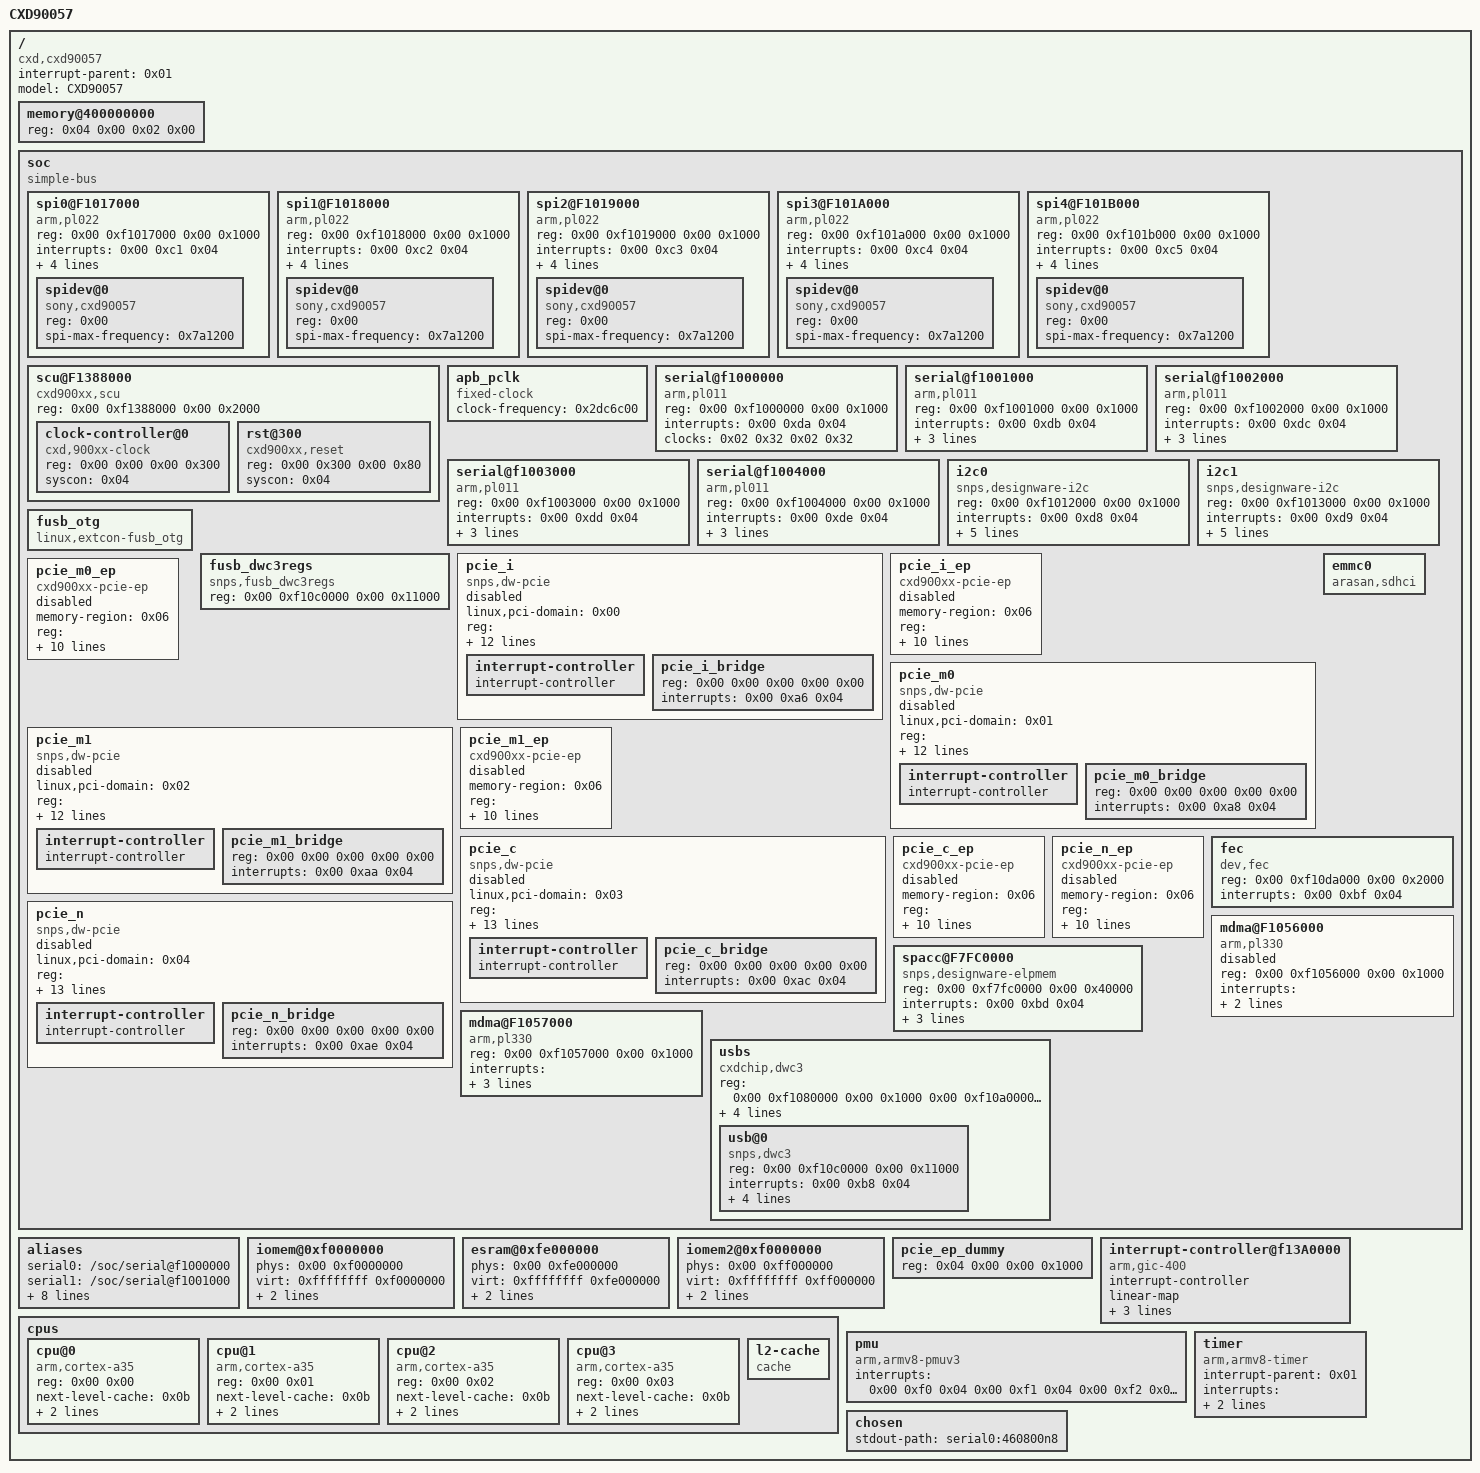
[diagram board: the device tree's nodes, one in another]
/dts-v1/;

/ {
	compatible = "cxd,cxd90057";
	interrupt-parent = <0x01>;
	#address-cells = <0x02>;
	#size-cells = <0x02>;
	model = "CXD90057";

	memory@400000000 {
		device_type = "memory";
		reg = <0x04 0x00 0x02 0x00>;
	};

	soc {
		compatible = "simple-bus";
		#address-cells = <0x02>;
		#size-cells = <0x02>;
		ranges;

		spi0@F1017000 {
			compatible = "arm,pl022", "arm,primecell";
			reg = <0x00 0xf1017000 0x00 0x1000>;
			interrupts = <0x00 0xc1 0x04>;
			#address-cells = <0x01>;
			#size-cells = <0x00>;
			num-cs = <0x01>;
			clocks = <0x02 0x0a 0x02 0x61 0x02 0x37 0x02 0x37>;
			clock-names = "spi_clk_parent", "spi_clk_sel", "spi_clk", "apb_pclk";
			resets = <0x03 0xac 0x03 0xad>;
			reset-names = "ssp", "apb";
			status = "okay";

			spidev@0 {
				compatible = "sony,cxd90057";
				reg = <0x00>;
				spi-max-frequency = <0x7a1200>;
			};
		};

		spi1@F1018000 {
			compatible = "arm,pl022", "arm,primecell";
			reg = <0x00 0xf1018000 0x00 0x1000>;
			interrupts = <0x00 0xc2 0x04>;
			#address-cells = <0x01>;
			#size-cells = <0x00>;
			num-cs = <0x01>;
			clocks = <0x02 0x0a 0x02 0x62 0x02 0x38 0x02 0x38>;
			clock-names = "spi_clk_parent", "spi_clk_sel", "spi_clk", "apb_pclk";
			resets = <0x03 0xae 0x03 0xaf>;
			reset-names = "ssp", "apb";
			status = "okay";

			spidev@0 {
				compatible = "sony,cxd90057";
				reg = <0x00>;
				spi-max-frequency = <0x7a1200>;
			};
		};

		spi2@F1019000 {
			compatible = "arm,pl022", "arm,primecell";
			reg = <0x00 0xf1019000 0x00 0x1000>;
			interrupts = <0x00 0xc3 0x04>;
			#address-cells = <0x01>;
			#size-cells = <0x00>;
			num-cs = <0x01>;
			clocks = <0x02 0x0a 0x02 0x63 0x02 0x39 0x02 0x39>;
			clock-names = "spi_clk_parent", "spi_clk_sel", "spi_clk", "apb_pclk";
			resets = <0x03 0xb0 0x03 0xb1>;
			reset-names = "ssp", "apb";
			status = "okay";

			spidev@0 {
				compatible = "sony,cxd90057";
				reg = <0x00>;
				spi-max-frequency = <0x7a1200>;
			};
		};

		spi3@F101A000 {
			compatible = "arm,pl022", "arm,primecell";
			reg = <0x00 0xf101a000 0x00 0x1000>;
			interrupts = <0x00 0xc4 0x04>;
			#address-cells = <0x01>;
			#size-cells = <0x00>;
			num-cs = <0x01>;
			clocks = <0x02 0x0a 0x02 0x64 0x02 0x3a 0x02 0x3a>;
			clock-names = "spi_clk_parent", "spi_clk_sel", "spi_clk", "apb_pclk";
			resets = <0x03 0xb2 0x03 0xb3>;
			reset-names = "ssp", "apb";
			status = "okay";

			spidev@0 {
				compatible = "sony,cxd90057";
				reg = <0x00>;
				spi-max-frequency = <0x7a1200>;
			};
		};

		spi4@F101B000 {
			compatible = "arm,pl022", "arm,primecell";
			reg = <0x00 0xf101b000 0x00 0x1000>;
			interrupts = <0x00 0xc5 0x04>;
			#address-cells = <0x01>;
			#size-cells = <0x00>;
			num-cs = <0x01>;
			clocks = <0x02 0x0a 0x02 0x65 0x02 0x3b 0x02 0x3b>;
			clock-names = "spi_clk_parent", "spi_clk_sel", "spi_clk", "apb_pclk";
			resets = <0x03 0xb4 0x03 0xb5>;
			reset-names = "ssp", "apb";
			status = "okay";

			spidev@0 {
				compatible = "sony,cxd90057";
				reg = <0x00>;
				spi-max-frequency = <0x7a1200>;
			};
		};

		scu@F1388000 {
			#address-cells = <0x02>;
			#size-cells = <0x02>;
			compatible = "cxd900xx,scu", "syscon", "simple-mfd";
			reg = <0x00 0xf1388000 0x00 0x2000>;
			ranges;
			linux,phandle = <0x04>;
			phandle = <0x04>;

			clock-controller@0 {
				compatible = "cxd,900xx-clock";
				reg = <0x00 0x00 0x00 0x300>;
				#clock-cells = <0x01>;
				syscon = <0x04>;
				linux,phandle = <0x02>;
				phandle = <0x02>;
			};

			rst@300 {
				compatible = "cxd900xx,reset";
				reg = <0x00 0x300 0x00 0x80>;
				#reset-cells = <0x01>;
				syscon = <0x04>;
				linux,phandle = <0x03>;
				phandle = <0x03>;
			};
		};

		apb_pclk {
			compatible = "fixed-clock";
			#clock-cells = <0x00>;
			clock-frequency = <0x2dc6c00>;
			linux,phandle = <0x09>;
			phandle = <0x09>;
		};

		serial@f1000000 {
			compatible = "arm,pl011", "arm,primecell";
			reg = <0x00 0xf1000000 0x00 0x1000>;
			interrupts = <0x00 0xda 0x04>;
			clocks = <0x02 0x32 0x02 0x32>;
			clock-names = "uartclk", "apb_pclk";
		};

		serial@f1001000 {
			compatible = "arm,pl011", "arm,primecell";
			reg = <0x00 0xf1001000 0x00 0x1000>;
			interrupts = <0x00 0xdb 0x04>;
			clocks = <0x02 0x33 0x02 0x33>;
			clock-names = "uartclk", "apb_pclk";
			assigned-clocks = <0x02 0x58>;
			assigned-clock-parents = <0x02 0x0a>;
		};

		serial@f1002000 {
			compatible = "arm,pl011", "arm,primecell";
			reg = <0x00 0xf1002000 0x00 0x1000>;
			interrupts = <0x00 0xdc 0x04>;
			clocks = <0x02 0x34 0x02 0x34>;
			clock-names = "uartclk", "apb_pclk";
			assigned-clocks = <0x02 0x59>;
			assigned-clock-parents = <0x02 0x0a>;
		};

		serial@f1003000 {
			compatible = "arm,pl011", "arm,primecell";
			reg = <0x00 0xf1003000 0x00 0x1000>;
			interrupts = <0x00 0xdd 0x04>;
			clocks = <0x02 0x35 0x02 0x35>;
			clock-names = "uartclk", "apb_pclk";
			assigned-clocks = <0x02 0x5a>;
			assigned-clock-parents = <0x02 0x0a>;
		};

		serial@f1004000 {
			compatible = "arm,pl011", "arm,primecell";
			reg = <0x00 0xf1004000 0x00 0x1000>;
			interrupts = <0x00 0xde 0x04>;
			clocks = <0x02 0x36 0x02 0x36>;
			clock-names = "uartclk", "apb_pclk";
			assigned-clocks = <0x02 0x5b>;
			assigned-clock-parents = <0x02 0x0a>;
		};

		i2c0 {
			#address-cells = <0x01>;
			#size-cells = <0x00>;
			compatible = "snps,designware-i2c";
			reg = <0x00 0xf1012000 0x00 0x1000>;
			interrupts = <0x00 0xd8 0x04>;
			clocks = <0x02 0x3c>;
			clock-names = "i2c_clk";
			clock-frequency = <0x61a80>;
			resets = <0x03 0xb8>;
			reset-names = "i2c_rst";
			i2c-scl-stuck-at-low-timeout = <0x16e3600>;
			i2c-sda-stuck-at-low-timeout = "", "\aS";
			status = "okay";
		};

		i2c1 {
			#address-cells = <0x01>;
			#size-cells = <0x00>;
			compatible = "snps,designware-i2c";
			reg = <0x00 0xf1013000 0x00 0x1000>;
			interrupts = <0x00 0xd9 0x04>;
			clocks = <0x02 0x3d>;
			clock-names = "i2c_clk";
			clock-frequency = <0x61a80>;
			resets = <0x03 0xb9>;
			reset-names = "i2c_rst";
			i2c-scl-stuck-at-low-timeout = "", "\aS";
			i2c-sda-stuck-at-low-timeout = "", "\aS";
			status = "okay";
		};

		fusb_otg {
			compatible = "linux,extcon-fusb_otg";
			linux,phandle = <0x0a>;
			phandle = <0x0a>;
		};

		fusb_dwc3regs {
			compatible = "snps,fusb_dwc3regs";
			reg = <0x00 0xf10c0000 0x00 0x11000>;
		};

		pcie_i {
			compatible = "snps,dw-pcie";
			linux,pci-domain = <0x00>;
			reg = <0x00 0xf7000000 0x00 0x380000 0x00 0xdffc0000 0x00 0x20000 0x00 0xf11c0000 0x00 0x40000>;
			reg-names = "ctrlreg", "config", "phy_reg";
			#address-cells = <0x03>;
			#size-cells = <0x02>;
			device_type = "pci";
			ranges = <0x82000000 0x00 0xdffe0000 0x00 0xdffe0000 0x00 0x10000>;
			interrupts = <0x00 0xa6 0x04 0x00 0xa6 0x04>;
			#interrupt-cells = <0x01>;
			interrupt-map-mask = <0x00 0x00 0x00 0x07>;
			interrupt-map = <0x00 0x00 0x00 0x00 0x01 0x00 0xa6 0x04 0x00 0x00 0x00 0x01 0x05 0x00 0x00 0x00 0x00 0x02 0x05 0x01 0x00 0x00 0x00 0x03 0x05 0x02 0x00 0x00 0x00 0x04 0x05 0x03>;
			firm-id = <0x01>;
			num-lanes = <0x04>;
			num-viewport = <0x08>;
			resets = <0x03 0x20 0x03 0x21 0x03 0x22 0x03 0x23 0x03 0x76 0x03 0x77>;
			reset-names = "rst_pwrup", "rst_button", "rst_pe", "rst_apb", "rst_axi2avb_pci", "rst_axi2avb_pci_i0";
			clocks = <0x02 0x3e 0x02 0x3f 0x02 0x40 0x02 0x41 0x02 0x42 0x02 0x1d 0x02 0x1e>;
			clock-names = "apb_pclk", "dbi_aclk", "slv_aclk", "mstr_aclk", "aux_clk", "axi2avb_pcie0", "axi2avb_pcie1";
			status = "disabled";

			interrupt-controller {
				interrupt-controller;
				#address-cells = <0x00>;
				#interrupt-cells = <0x01>;
				linux,phandle = <0x05>;
				phandle = <0x05>;
			};

			pcie_i_bridge {
				reg = <0x00 0x00 0x00 0x00 0x00>;
				interrupts = <0x00 0xa6 0x04>;
			};
		};

		pcie_i_ep {
			compatible = "cxd900xx-pcie-ep";
			memory-region = <0x06>;
			reg = <0x00 0xf7000000 0x00 0x400000 0x00 0xf7100000 0x00 0x10000 0x00 0xf11c0000 0x00 0x40000>;
			reg-names = "ctrlreg", "ctrlreg_shadow", "phy_reg";
			interrupts = <0x00 0xa6 0x04>;
			firm-id = <0x01>;
			num-lanes = <0x04>;
			num-ib-windows = <0x08>;
			num-ob-windows = <0x08>;
			resets = <0x03 0x20 0x03 0x21 0x03 0x22 0x03 0x23 0x03 0x76 0x03 0x77>;
			reset-names = "rst_pwrup", "rst_button", "rst_pe", "rst_apb", "rst_axi2avb_pci", "rst_axi2avb_pci_i0";
			clocks = <0x02 0x3e 0x02 0x3f 0x02 0x40 0x02 0x41 0x02 0x42 0x02 0x1d 0x02 0x1e>;
			clock-names = "apb_pclk", "dbi_aclk", "slv_aclk", "mstr_aclk", "aux_clk", "axi2avb_pcie0", "axi2avb_pcie1";
			status = "disabled";
		};

		pcie_m0 {
			compatible = "snps,dw-pcie";
			linux,pci-domain = <0x01>;
			reg = <0x00 0xf6800000 0x00 0x380000 0x00 0xc8010000 0x00 0x20000 0x00 0xf1140000 0x00 0x40000>;
			reg-names = "ctrlreg", "config", "phy_reg";
			#address-cells = <0x03>;
			#size-cells = <0x02>;
			device_type = "pci";
			ranges = <0x82000000 0x00 0xc8030000 0x00 0xc8030000 0x00 0x3fe0000 0xc2000000 0x00 0xcc010000 0x00 0xcc010000 0x00 0x3fe0000>;
			interrupts = <0x00 0xa8 0x04 0x00 0xa8 0x04>;
			#interrupt-cells = <0x01>;
			interrupt-map-mask = <0x00 0x00 0x00 0x07>;
			interrupt-map = <0x00 0x00 0x00 0x00 0x01 0x00 0xa8 0x04>;
			firm-id = <0x01>;
			num-lanes = <0x02>;
			num-viewport = <0x08>;
			resets = <0x03 0x28 0x03 0x29 0x03 0x2a 0x03 0x2b 0x03 0x76 0x03 0x77>;
			reset-names = "rst_pwrup", "rst_button", "rst_pe", "rst_apb", "rst_axi2avb_pci", "rst_axi2avb_pci_i0";
			clocks = <0x02 0x43 0x02 0x44 0x02 0x45 0x02 0x46 0x02 0x47 0x02 0x1d 0x02 0x1e>;
			clock-names = "apb_pclk", "dbi_aclk", "slv_aclk", "mstr_aclk", "aux_clk", "axi2avb_pcie0", "axi2avb_pcie1";
			status = "disabled";

			interrupt-controller {
				interrupt-controller;
				#address-cells = <0x00>;
				#interrupt-cells = <0x01>;
			};

			pcie_m0_bridge {
				reg = <0x00 0x00 0x00 0x00 0x00>;
				interrupts = <0x00 0xa8 0x04>;
			};
		};

		pcie_m0_ep {
			compatible = "cxd900xx-pcie-ep";
			memory-region = <0x06>;
			reg = <0x00 0xf6800000 0x00 0x400000 0x00 0xf6900000 0x00 0x10000 0x00 0xf1140000 0x00 0x40000>;
			reg-names = "ctrlreg", "ctrlreg_shadow", "phy_reg";
			interrupts = <0x00 0xa8 0x04>;
			firm-id = <0x01>;
			num-lanes = <0x02>;
			num-ib-windows = <0x08>;
			num-ob-windows = <0x08>;
			resets = <0x03 0x28 0x03 0x29 0x03 0x2a 0x03 0x2b 0x03 0x76 0x03 0x77>;
			reset-names = "rst_pwrup", "rst_button", "rst_pe", "rst_apb", "rst_axi2avb_pci", "rst_axi2avb_pci_i0";
			clocks = <0x02 0x43 0x02 0x44 0x02 0x45 0x02 0x46 0x02 0x47 0x02 0x1d 0x02 0x1e>;
			clock-names = "apb_pclk", "dbi_aclk", "slv_aclk", "mstr_aclk", "aux_clk", "axi2avb_pcie0", "axi2avb_pcie1";
			status = "disabled";
		};

		pcie_m1 {
			compatible = "snps,dw-pcie";
			linux,pci-domain = <0x02>;
			reg = <0x00 0xf6c00000 0x00 0x380000 0x00 0xd0010000 0x00 0x20000 0x00 0xf1180000 0x00 0x40000>;
			reg-names = "ctrlreg", "config", "phy_reg";
			#address-cells = <0x03>;
			#size-cells = <0x02>;
			device_type = "pci";
			ranges = <0x82000000 0x00 0xd0030000 0x00 0xd0030000 0x00 0x3fe0000 0xc2000000 0x00 0xd4010000 0x00 0xd4010000 0x00 0x3fe0000>;
			interrupts = <0x00 0xaa 0x04 0x00 0xaa 0x04>;
			#interrupt-cells = <0x01>;
			interrupt-map-mask = <0x00 0x00 0x00 0x07>;
			interrupt-map = <0x00 0x00 0x00 0x00 0x01 0x00 0xaa 0x04>;
			firm-id = <0x01>;
			num-lanes = <0x02>;
			num-viewport = <0x08>;
			resets = <0x03 0x24 0x03 0x25 0x03 0x26 0x03 0x27 0x03 0x76 0x03 0x77>;
			reset-names = "rst_pwrup", "rst_button", "rst_pe", "rst_apb", "rst_axi2avb_pci", "rst_axi2avb_pci_i0";
			clocks = <0x02 0x48 0x02 0x49 0x02 0x4a 0x02 0x4b 0x02 0x4c 0x02 0x1d 0x02 0x1e>;
			clock-names = "apb_pclk", "dbi_aclk", "slv_aclk", "mstr_aclk", "aux_clk", "axi2avb_pcie0", "axi2avb_pcie1";
			status = "disabled";

			interrupt-controller {
				interrupt-controller;
				#address-cells = <0x00>;
				#interrupt-cells = <0x01>;
			};

			pcie_m1_bridge {
				reg = <0x00 0x00 0x00 0x00 0x00>;
				interrupts = <0x00 0xaa 0x04>;
			};
		};

		pcie_m1_ep {
			compatible = "cxd900xx-pcie-ep";
			memory-region = <0x06>;
			reg = <0x00 0xf6c00000 0x00 0x400000 0x00 0xf6d00000 0x00 0x10000 0x00 0xf1180000 0x00 0x40000>;
			reg-names = "ctrlreg", "ctrlreg_shadow", "phy_reg";
			interrupts = <0x00 0xaa 0x04>;
			firm-id = <0x01>;
			num-lanes = <0x02>;
			num-ib-windows = <0x08>;
			num-ob-windows = <0x08>;
			resets = <0x03 0x24 0x03 0x25 0x03 0x26 0x03 0x27 0x03 0x76 0x03 0x77>;
			reset-names = "rst_pwrup", "rst_button", "rst_pe", "rst_apb", "rst_axi2avb_pci", "rst_axi2avb_pci_i0";
			clocks = <0x02 0x48 0x02 0x49 0x02 0x4a 0x02 0x4b 0x02 0x4c 0x02 0x1d 0x02 0x1e>;
			clock-names = "apb_pclk", "dbi_aclk", "slv_aclk", "mstr_aclk", "aux_clk", "axi2avb_pcie0", "axi2avb_pcie1";
			status = "disabled";
		};

		pcie_c {
			compatible = "snps,dw-pcie";
			linux,pci-domain = <0x03>;
			reg = <0x00 0xf7400000 0x00 0x380000 0x00 0xe0000000 0x00 0x20000 0x00 0xf1200000 0x00 0x40000>;
			reg-names = "ctrlreg", "config", "phy_reg";
			#address-cells = <0x03>;
			#size-cells = <0x02>;
			device_type = "pci";
			cxd90057,pci32;
			ranges = <0x82000000 0x00 0xe0020000 0x00 0xe0020000 0x00 0x3ff0000 0xc2000000 0x00 0xe4010000 0x00 0xe4010000 0x00 0x3ff0000>;
			interrupts = <0x00 0xac 0x04 0x00 0xac 0x04>;
			#interrupt-cells = <0x01>;
			interrupt-map-mask = <0x00 0x00 0x00 0x07>;
			interrupt-map = <0x00 0x00 0x00 0x00 0x01 0x00 0xac 0x04 0x00 0x00 0x00 0x01 0x07 0x00 0x00 0x00 0x00 0x02 0x07 0x01 0x00 0x00 0x00 0x03 0x07 0x02 0x00 0x00 0x00 0x04 0x07 0x03>;
			firm-id = <0x01>;
			num-lanes = <0x01>;
			num-viewport = <0x08>;
			resets = <0x03 0x2c 0x03 0x2d 0x03 0x2e 0x03 0x2f 0x03 0x76 0x03 0x77>;
			reset-names = "rst_pwrup", "rst_button", "rst_pe", "rst_apb", "rst_axi2avb_pci", "rst_axi2avb_pci_i0";
			clocks = <0x02 0x4d 0x02 0x4e 0x02 0x4f 0x02 0x50 0x02 0x51 0x02 0x1d 0x02 0x1e>;
			clock-names = "apb_pclk", "dbi_aclk", "slv_aclk", "mstr_aclk", "aux_clk", "axi2avb_pcie0", "axi2avb_pcie1";
			status = "disabled";

			interrupt-controller {
				interrupt-controller;
				#address-cells = <0x00>;
				#interrupt-cells = <0x01>;
				linux,phandle = <0x07>;
				phandle = <0x07>;
			};

			pcie_c_bridge {
				reg = <0x00 0x00 0x00 0x00 0x00>;
				interrupts = <0x00 0xac 0x04>;
			};
		};

		pcie_c_ep {
			compatible = "cxd900xx-pcie-ep";
			memory-region = <0x06>;
			reg = <0x00 0xf7400000 0x00 0x400000 0x00 0xf7500000 0x00 0x10000 0x00 0xf1200000 0x00 0x40000>;
			reg-names = "ctrlreg", "ctrlreg_shadow", "phy_reg";
			interrupts = <0x00 0xac 0x04>;
			firm-id = <0x01>;
			num-lanes = <0x01>;
			num-ib-windows = <0x08>;
			num-ob-windows = <0x08>;
			resets = <0x03 0x2c 0x03 0x2d 0x03 0x2e 0x03 0x2f 0x03 0x76 0x03 0x77>;
			reset-names = "rst_pwrup", "rst_button", "rst_pe", "rst_apb", "rst_axi2avb_pci", "rst_axi2avb_pci_i0";
			clocks = <0x02 0x4d 0x02 0x4e 0x02 0x4f 0x02 0x50 0x02 0x51 0x02 0x1d 0x02 0x1e>;
			clock-names = "apb_pclk", "dbi_aclk", "slv_aclk", "mstr_aclk", "aux_clk", "axi2avb_pcie0", "axi2avb_pcie1";
			status = "disabled";
		};

		pcie_n {
			compatible = "snps,dw-pcie";
			linux,pci-domain = <0x04>;
			reg = <0x00 0xf6400000 0x00 0x380000 0x00 0xc0000000 0x00 0x20000 0x00 0xf1100000 0x00 0x40000>;
			reg-names = "ctrlreg", "config", "phy_reg";
			#address-cells = <0x03>;
			#size-cells = <0x02>;
			device_type = "pci";
			cxd90057,pci32;
			ranges = <0x82000000 0x00 0xc2000000 0x00 0xc2000000 0x00 0x3000000 0xc2000000 0x00 0xc5000000 0x00 0xc5000000 0x00 0x3000000>;
			interrupts = <0x00 0xae 0x04 0x00 0xae 0x04>;
			#interrupt-cells = <0x01>;
			interrupt-map-mask = <0x00 0x00 0x00 0x07>;
			interrupt-map = <0x00 0x00 0x00 0x00 0x01 0x00 0xae 0x04 0x00 0x00 0x00 0x01 0x08 0x00 0x00 0x00 0x00 0x02 0x08 0x01 0x00 0x00 0x00 0x03 0x08 0x02 0x00 0x00 0x00 0x04 0x08 0x03>;
			firm-id = <0x01>;
			num-lanes = <0x01>;
			num-viewport = <0x08>;
			resets = <0x03 0x30 0x03 0x31 0x03 0x32 0x03 0x33 0x03 0x76 0x03 0x77>;
			reset-names = "rst_pwrup", "rst_button", "rst_pe", "rst_apb", "rst_axi2avb_pci", "rst_axi2avb_pci_i0";
			clocks = <0x02 0x52 0x02 0x53 0x02 0x54 0x02 0x55 0x02 0x56 0x02 0x1d 0x02 0x1e>;
			clock-names = "apb_pclk", "dbi_aclk", "slv_aclk", "mstr_aclk", "aux_clk", "axi2avb_pcie0", "axi2avb_pcie1";
			status = "disabled";

			interrupt-controller {
				interrupt-controller;
				#address-cells = <0x00>;
				#interrupt-cells = <0x01>;
				linux,phandle = <0x08>;
				phandle = <0x08>;
			};

			pcie_n_bridge {
				reg = <0x00 0x00 0x00 0x00 0x00>;
				interrupts = <0x00 0xae 0x04>;
			};
		};

		pcie_n_ep {
			compatible = "cxd900xx-pcie-ep";
			memory-region = <0x06>;
			reg = <0x00 0xf6400000 0x00 0x400000 0x00 0xf6500000 0x00 0x10000 0x00 0xf1100000 0x00 0x40000>;
			reg-names = "ctrlreg", "ctrlreg_shadow", "phy_reg";
			interrupts = <0x00 0xae 0x04>;
			firm-id = <0x01>;
			num-lanes = <0x01>;
			num-ib-windows = <0x08>;
			num-ob-windows = <0x08>;
			resets = <0x03 0x30 0x03 0x31 0x03 0x32 0x03 0x33 0x03 0x76 0x03 0x77>;
			reset-names = "rst_pwrup", "rst_button", "rst_pe", "rst_apb", "rst_axi2avb_pci", "rst_axi2avb_pci_i0";
			clocks = <0x02 0x52 0x02 0x53 0x02 0x54 0x02 0x55 0x02 0x56 0x02 0x1d 0x02 0x1e>;
			clock-names = "apb_pclk", "dbi_aclk", "slv_aclk", "mstr_aclk", "aux_clk", "axi2avb_pcie0", "axi2avb_pcie1";
			status = "disabled";
		};

		emmc0 {
			compatible = "arasan,sdhci";
		};

		fec {
			compatible = "dev,fec";
			reg = <0x00 0xf10da000 0x00 0x2000>;
			interrupts = <0x00 0xbf 0x04>;
		};

		spacc@F7FC0000 {
			compatible = "snps,designware-elpmem";
			reg = <0x00 0xf7fc0000 0x00 0x40000>;
			interrupts = <0x00 0xbd 0x04>;
			dma-coherent;
			clocks = <0x02 0x19>;
			resets = <0x03 0x15>;
			status = "okay";
		};

		mdma@F1056000 {
			compatible = "arm,pl330", "arm,primecell";
			reg = <0x00 0xf1056000 0x00 0x1000>;
			interrupts = <0x00 0x50 0x04 0x00 0x51 0x04 0x00 0x52 0x04 0x00 0x53 0x04 0x00 0x54 0x04 0x00 0x55 0x04 0x00 0x56 0x04 0x00 0x57 0x04>;
			clocks = <0x09>;
			clock-names = "apb_pclk";
			status = "disabled";
			#dma-cells = <0x01>;
		};

		mdma@F1057000 {
			compatible = "arm,pl330", "arm,primecell";
			reg = <0x00 0xf1057000 0x00 0x1000>;
			interrupts = <0x00 0x71 0x04 0x00 0x72 0x04 0x00 0x73 0x04 0x00 0x74 0x04 0x00 0x75 0x04 0x00 0x76 0x04 0x00 0x77 0x04 0x00 0x78 0x04>;
			clocks = <0x09>;
			clock-names = "apb_pclk";
			status = "ok";
			#dma-cells = <0x01>;
			arm,pl330-broken-no-flushp;
		};

		usbs {
			compatible = "cxdchip,dwc3";
			reg = <0x00 0xf1080000 0x00 0x1000 0x00 0xf10a0000 0x00 0x1c000>;
			reg-names = "ss_usb", "phy_cr";
			clocks = <0x02 0x13 0x02 0x12 0x02 0x11 0x02 0x10>;
			clock-names = "usb_sus_clk", "usb_axi_clk", "usb_apb_clk", "usb_refclk";
			resets = <0x03 0x0b 0x03 0x0a 0x03 0x09 0x03 0x08>;
			reset-names = "rst_u31", "rst_u2", "rst_apb", "rst_axi";
			#address-cells = <0x02>;
			#size-cells = <0x02>;
			ranges;

			usb@0 {
				compatible = "snps,dwc3";
				reg = <0x00 0xf10c0000 0x00 0x11000>;
				interrupts = <0x00 0xb8 0x04>;
				dr_mode = "otg";
				maximum-speed = "super-speed-plus";
				phy_type = "utmi";
				extcon = <0x0a>;
				status = "okay";
			};
		};
	};

	aliases {
		serial0 = "/soc/serial@f1000000";
		serial1 = "/soc/serial@f1001000";
		serial2 = "/soc/serial@f1002000";
		serial3 = "/soc/serial@f1003000";
		serial4 = "/soc/serial@f1004000";
		spi0 = "/soc/spi0@F1017000";
		spi1 = "/soc/spi1@F1018000";
		spi2 = "/soc/spi2@F1019000";
		spi3 = "/soc/spi3@F101A000";
		spi4 = "/soc/spi4@F101B000";
	};

	iomem@0xf0000000 {
		device_type = "iomap";
		phys = <0x00 0xf0000000>;
		virt = <0xffffffff 0xf0000000>;
		size = <0x00 0xe000000>;
		memtype = <0x01>;
	};

	esram@0xfe000000 {
		device_type = "iomap";
		phys = <0x00 0xfe000000>;
		virt = <0xffffffff 0xfe000000>;
		size = <0x00 0x1000000>;
		memtype = <0x03>;
	};

	iomem2@0xf0000000 {
		device_type = "iomap";
		phys = <0x00 0xff000000>;
		virt = <0xffffffff 0xff000000>;
		size = <0x00 0x1000000>;
		memtype = <0x01>;
	};

	pcie_ep_dummy {
		reg = <0x04 0x00 0x00 0x1000>;
		linux,phandle = <0x06>;
		phandle = <0x06>;
	};

	cpus {
		#address-cells = <0x02>;
		#size-cells = <0x00>;

		cpu@0 {
			device_type = "cpu";
			compatible = "arm,cortex-a35", "arm,armv8";
			reg = <0x00 0x00>;
			next-level-cache = <0x0b>;
			enable-method = "spin-table";
			cpu-release-addr = <0x00 0x00>;
		};

		cpu@1 {
			device_type = "cpu";
			compatible = "arm,cortex-a35", "arm,armv8";
			reg = <0x00 0x01>;
			next-level-cache = <0x0b>;
			enable-method = "spin-table";
			cpu-release-addr = <0x00 0x00>;
		};

		cpu@2 {
			device_type = "cpu";
			compatible = "arm,cortex-a35", "arm,armv8";
			reg = <0x00 0x02>;
			next-level-cache = <0x0b>;
			enable-method = "spin-table";
			cpu-release-addr = <0x00 0x00>;
		};

		cpu@3 {
			device_type = "cpu";
			compatible = "arm,cortex-a35", "arm,armv8";
			reg = <0x00 0x03>;
			next-level-cache = <0x0b>;
			enable-method = "spin-table";
			cpu-release-addr = <0x00 0x00>;
		};

		l2-cache {
			compatible = "cache";
			linux,phandle = <0x0b>;
			phandle = <0x0b>;
		};
	};

	interrupt-controller@f13A0000 {
		compatible = "arm,gic-400";
		#interrupt-cells = <0x03>;
		interrupt-controller;
		linear-map;
		reg = <0x00 0xf13a1000 0x00 0x1000 0x00 0xf13a2000 0x00 0x2000 0x00 0xf13a4000 0x00 0x2000 0x00 0xf13a6000 0x00 0x2000>;
		interrupts = <0x01 0x09 0x308>;
		linux,phandle = <0x01>;
		phandle = <0x01>;
	};

	pmu {
		compatible = "arm,armv8-pmuv3";
		interrupts = <0x00 0xf0 0x04 0x00 0xf1 0x04 0x00 0xf2 0x04 0x00 0xf3 0x04>;
	};

	timer {
		compatible = "arm,armv8-timer";
		interrupt-parent = <0x01>;
		interrupts = <0x01 0x0d 0x308 0x01 0x0e 0x308 0x01 0x0b 0x308 0x01 0x0a 0x308>;
		clock-frequency = <0x1e8480>;
	};

	chosen {
		stdout-path = "serial0:460800n8";
	};
};
